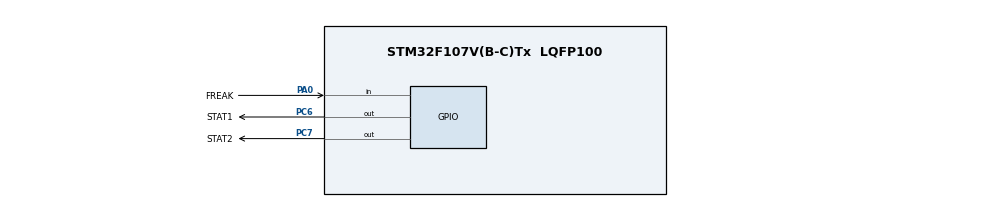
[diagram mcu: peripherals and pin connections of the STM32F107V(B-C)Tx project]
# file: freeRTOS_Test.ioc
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FREERTOS.INCLUDE_vTaskDelayUntil=1
FREERTOS.Tasks01=defaultTask,0,128,StartDefaultTask,Default,NULL,Dynamic,NULL,NULL
FREERTOS.configUSE_NEWLIB_REENTRANT=1
Mcu.Family=STM32F1
Mcu.Name=STM32F107V(B-C)Tx
Mcu.Package=LQFP100
NVIC.PriorityGroup=NVIC_PRIORITYGROUP_4
NVIC.TIM1_UP_IRQn=true\:15\:0\:false\:false\:true\:false\:false\:true
NVIC.TimeBase=TIM1_UP_IRQn
NVIC.TimeBaseIP=TIM1
OSC_IN.Mode=HSE-External-Oscillator
OSC_IN.Signal=RCC_OSC_IN
OSC_OUT.Mode=HSE-External-Oscillator
OSC_OUT.Signal=RCC_OSC_OUT
PA0-WKUP.GPIO_Label=FREAK
PA0-WKUP.Signal=GPIO_Input
PA13.Mode=JTAG_5_pins
PA13.Signal=SYS_JTMS-SWDIO
PA14.Mode=JTAG_5_pins
PA14.Signal=SYS_JTCK-SWCLK
PA15.Mode=JTAG_5_pins
PA15.Signal=SYS_JTDI
PB3.Mode=JTAG_5_pins
PB3.Signal=SYS_JTDO
PB4.Mode=JTAG_5_pins
PB4.Signal=SYS_NJTRST
PC6.GPIO_Label=STAT1
PC6.GPIO_PuPd=GPIO_NOPULL
PC6.Signal=GPIO_Output
PC7.GPIO_Label=STAT2
PC7.Signal=GPIO_Output
ProjectManager.HeapSize=0x200
ProjectManager.StackSize=0x400
ProjectManager.TargetToolchain=STM32CubeIDE
RCC.HSE_VALUE=25000000
RCC.USBFreq_Value=10666666.666666666
VP_FREERTOS_VS_CMSIS_V1.Mode=CMSIS_V1
VP_SYS_VS_tim1.Mode=TIM1
board=custom

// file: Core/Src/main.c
/* USER CODE BEGIN Header */
/**
  ******************************************************************************
  * @file           : main.c
  * @brief          : Main program body
  ******************************************************************************
  * @attention
  *
  * <h2><center>&copy; Copyright (c) 2021 STMicroelectronics.
  * All rights reserved.</center></h2>
  *
  * This software component is licensed by ST under BSD 3-Clause license,
  * the "License"; You may not use this file except in compliance with the
  * License. You may obtain a copy of the License at:
  *                        opensource.org/licenses/BSD-3-Clause
  *
  ******************************************************************************
  */
/* USER CODE END Header */
#include "main.h"
#include "cmsis_os.h"

osThreadId defaultTaskHandle;
/* USER CODE BEGIN PV */
osThreadId Task2Handle;
osThreadId TaskButtonHandle;
/* USER CODE END PV */

void SystemClock_Config(void);
static void MX_GPIO_Init(void);
void StartDefaultTask(void const * argument);

/* USER CODE BEGIN PFP */
void Task2_init(void const * argument);
void TaskButton_init(void const * argument);
/* USER CODE END PFP */

int main(void)
{

  /* MCU Configuration--------------------------------------------------------*/

  /* Reset of all peripherals, Initializes the Flash interface and the Systick. */
  HAL_Init();

  /* Configure the system clock */
  SystemClock_Config();

  /* Initialize all configured peripherals */
  MX_GPIO_Init();

  /* Create the thread(s) */
  /* definition and creation of defaultTask */
  osThreadDef(defaultTask, StartDefaultTask, osPriorityNormal, 0, 128);
  defaultTaskHandle = osThreadCreate(osThread(defaultTask), NULL);

  /* USER CODE BEGIN RTOS_THREADS */
  //osThreadDef(Task2, Task2_init, osPriorityBelowNormal,0, 128);
  //Task2Handle = osThreadCreate(osThread(Task2), NULL);

  osThreadDef(TaskButton, TaskButton_init, osPriorityNormal,0, 128);
  TaskButtonHandle = osThreadCreate(osThread(TaskButton), NULL);
  /* USER CODE END RTOS_THREADS */

  /* Start scheduler */
  osKernelStart();

  /* We should never get here as control is now taken by the scheduler */
  /* Infinite loop */
  while (1)
  {

  }
}

void SystemClock_Config(void)
{
  RCC_OscInitTypeDef RCC_OscInitStruct = {0};
  RCC_ClkInitTypeDef RCC_ClkInitStruct = {0};

  /** Initializes the RCC Oscillators according to the specified parameters
  * in the RCC_OscInitTypeDef structure.
  */
  RCC_OscInitStruct.OscillatorType = RCC_OSCILLATORTYPE_HSI;
  RCC_OscInitStruct.HSIState = RCC_HSI_ON;
  RCC_OscInitStruct.HSICalibrationValue = RCC_HSICALIBRATION_DEFAULT;
  RCC_OscInitStruct.PLL.PLLState = RCC_PLL_NONE;
  RCC_OscInitStruct.PLL2.PLL2State = RCC_PLL_NONE;
  if (HAL_RCC_OscConfig(&RCC_OscInitStruct) != HAL_OK)
  {
    Error_Handler();
  }
  /** Initializes the CPU, AHB and APB buses clocks
  */
  RCC_ClkInitStruct.ClockType = RCC_CLOCKTYPE_HCLK|RCC_CLOCKTYPE_SYSCLK
                              |RCC_CLOCKTYPE_PCLK1|RCC_CLOCKTYPE_PCLK2;
  RCC_ClkInitStruct.SYSCLKSource = RCC_SYSCLKSOURCE_HSI;
  RCC_ClkInitStruct.AHBCLKDivider = RCC_SYSCLK_DIV1;
  RCC_ClkInitStruct.APB1CLKDivider = RCC_HCLK_DIV1;
  RCC_ClkInitStruct.APB2CLKDivider = RCC_HCLK_DIV1;

  if (HAL_RCC_ClockConfig(&RCC_ClkInitStruct, FLASH_LATENCY_0) != HAL_OK)
  {
    Error_Handler();
  }
  /** Configure the Systick interrupt time
  */
  __HAL_RCC_PLLI2S_ENABLE();
}

static void MX_GPIO_Init(void)
{
  GPIO_InitTypeDef GPIO_InitStruct = {0};

  /* GPIO Ports Clock Enable */
  __HAL_RCC_GPIOA_CLK_ENABLE();
  __HAL_RCC_GPIOC_CLK_ENABLE();
  __HAL_RCC_GPIOB_CLK_ENABLE();

  /*Configure GPIO pin Output Level */
  HAL_GPIO_WritePin(GPIOC, STAT1_Pin|STAT2_Pin, GPIO_PIN_RESET);

  /*Configure GPIO pin : FREAK_Pin */
  GPIO_InitStruct.Pin = FREAK_Pin;
  GPIO_InitStruct.Mode = GPIO_MODE_INPUT;
  GPIO_InitStruct.Pull = GPIO_NOPULL;
  HAL_GPIO_Init(FREAK_GPIO_Port, &GPIO_InitStruct);

  /*Configure GPIO pins : STAT1_Pin STAT2_Pin */
  GPIO_InitStruct.Pin = STAT1_Pin|STAT2_Pin;
  GPIO_InitStruct.Mode = GPIO_MODE_OUTPUT_PP;
  GPIO_InitStruct.Pull = GPIO_NOPULL;
  GPIO_InitStruct.Speed = GPIO_SPEED_FREQ_LOW;
  HAL_GPIO_Init(GPIOC, &GPIO_InitStruct);

}

void StartDefaultTask(void const * argument)
{
  /* USER CODE BEGIN 5 */
  /* Infinite loop */
	for(;;)
	{
		HAL_GPIO_TogglePin(GPIOC, STAT1_Pin|STAT2_Pin);
		//HAL_Delay(250);
		//osDelay(250);
		vTaskDelay(250 / portTICK_PERIOD_MS);
	}
  /* USER CODE END 5 */
}

void Task2_init(void const * argument)
{

	while(1)
	{
		HAL_GPIO_WritePin(GPIOC, STAT1_Pin|STAT2_Pin, GPIO_PIN_SET);
		//HAL_Delay(432);
		//osDelay(233);
		vTaskDelay(233 / portTICK_PERIOD_MS);
		HAL_GPIO_WritePin(GPIOC, STAT1_Pin|STAT2_Pin, GPIO_PIN_RESET);
		//HAL_Delay(432);
		//osDelay(233);
		vTaskDelay(233 / portTICK_PERIOD_MS);
	}
}

void TaskButton_init(void const * argument)
{
	GPIO_PinState currentState;

	while(1)
	{
		currentState = HAL_GPIO_ReadPin(GPIOA, FREAK_Pin);

		if (currentState == GPIO_PIN_SET)
		{
			HAL_GPIO_TogglePin(GPIOC, STAT1_Pin|STAT2_Pin);
			//HAL_Delay(100);
			//osDelay(100);
			vTaskDelay(30 / portTICK_PERIOD_MS);
		}
		vTaskDelay(10 / portTICK_PERIOD_MS);
	}
}

void HAL_TIM_PeriodElapsedCallback(TIM_HandleTypeDef *htim)
{
  if (htim->Instance == TIM1) {
    HAL_IncTick();
  }
}

void Error_Handler(void)
{
  __disable_irq();
  while (1)
  {
  }
}

/************************ (C) COPYRIGHT STMicroelectronics *****END OF FILE****/
